# ESP32-S31 register map
Vendor: ESPRESSIF SYSTEMS (SHANGHAI) CO., LTD.; Series: ESP32 S-Series; File version: 1
CPU: RV32IMAFC r0p0, little endian, no MPU, FPU, 0 interrupt priority bits
Address unit: 32 bits
Registers are 32-bit, read-write, reset 0x0 unless marked. A register's access mark holds for its fields unless they carry their own. Offsets are from the block's base; [hi:lo] are bit positions; {n}, {i} and the like mark numbered series.

## LEDC0 — LEDC0 Peripheral
Base 0x20392000
Same registers: LEDC1 0x2039C000
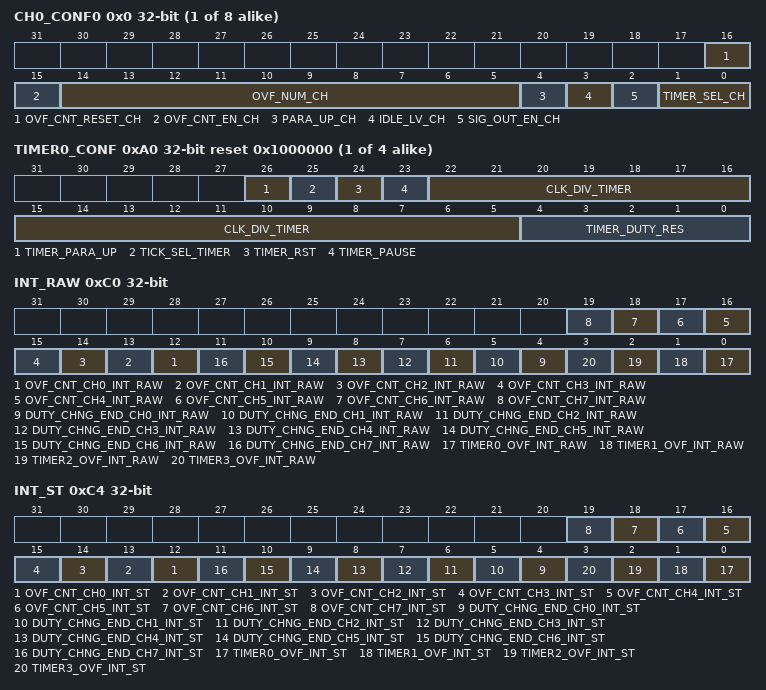
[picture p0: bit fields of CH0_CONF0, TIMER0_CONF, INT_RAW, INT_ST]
{0x0+0x14*i} CH{i}_CONF0 (i=0..7) access per field — Configuration register 0 for channel {i}
  [16] OVF_CNT_RESET_CH wo — Configures whether or not to reset the ovf_cnt of channel %s.\\0: Invalid. No effect\\1: Reset the ovf_cnt
  [15] OVF_CNT_EN_CH rw — Configures whether or not to enable the ovf_cnt of channel %s.\\0: Disable\\1: Enable
  [14:5] OVF_NUM_CH rw — Configures the maximum times of overflow minus 1.The LEDC_OVF_CNT_CH%s_INT interrupt will be triggered when channel %s overflows for (LEDC_OVF_NUM_CH%s + 1) times.
  [4] PARA_UP_CH wo — Configures whether or not to update LEDC_HPOINT_CH%s, LEDC_DUTY_START_CH%s, LEDC_SIG_OUT_EN_CH%s, LEDC_TIMER_SEL_CH%s, LEDC_OVF_CNT_EN_CH%s fields and duty cycle range configuration for channel %s, and will be automatically cleared by hardware.\\0: Invalid. No effect\\1: Update
  [3] IDLE_LV_CH rw — Configures the output value when channel %s is inactive. Valid only when LEDC_SIG_OUT_EN_CH%s is 0.\\0: Output level is low\\1: Output level is high
  [2] SIG_OUT_EN_CH rw — Configures whether or not to enable signal output on channel %s.\\0: Signal output disable\\1: Signal output enable
  [1:0] TIMER_SEL_CH rw — Configures which timer is channel %s selected.\\0: Select timer0\\1: Select timer1\\2: Select timer2\\3: Select timer3
{0x4+0x14*i} CH{i}_HPOINT (i=0..7) — High point register for channel {i}
  [19:0] HPOINT_CH — Configures high point of signal output on channel %s. The output value changes to high when the selected timers has reached the value specified by this register.
{0x8+0x14*i} CH{i}_DUTY (i=0..7) — Initial duty cycle register for channel {i}
  [24:0] DUTY_CH — Configures the duty of signal output on channel %s.
{0xC+0x14*i} CH{i}_CONF1 (i=0..7) — Configuration register 1 for channel {i}
  [31] DUTY_START_CH — Configures whether the duty cycle fading configurations take effect.\\0: Not take effect\\1: Take effect
{0x10+0x14*i} CH{i}_DUTY_R (i=0..7) ro — Current duty cycle register for channel {i}
  [24:0] DUTY_CH_R — Represents the current duty of output signal on channel %s.
{0xA0+8i} TIMER{i}_CONF (i=0..3) access per field reset 0x1000000 — Timer {i} configuration register
  [26] TIMER_PARA_UP wo — Configures whether or not to update LEDC_CLK_DIV_TIMER%s and LEDC_TIMER%s_DUTY_RES.\\0: Invalid. No effect\\1: Update
  [25] TICK_SEL_TIMER rw — Configures which clock is timer %s selected. Unused.
  [24] TIMER_RST rw — Configures whether or not to reset timer %s. The counter will show 0 after reset.\\0: Not reset\\1: Reset
  [23] TIMER_PAUSE rw — Configures whether or not to pause the counter in timer %s.\\0: Normal\\1: Pause
  [22:5] CLK_DIV_TIMER rw — Configures the divisor for the divider in timer %s.The least significant eight bits represent the fractional part.
  [4:0] TIMER_DUTY_RES rw — Configures the bit width of the counter in timer %s. Valid values are 1 to 20.
{0xA4+8i} TIMER{i}_VALUE (i=0..3) ro — Timer {i} current counter value register
  [19:0] TIMER_CNT — Represents the current counter value of timer %s.
0xC0 INT_RAW — Interrupt raw status register
  [n+12] OVF_CNT_CH{n}_INT_RAW (n=0..7) — Raw status bit: The raw interrupt status of LEDC_OVF_CNT_CH{n}_INT. Triggered when the ovf_cnt has reached the value specified by LEDC_OVF_NUM_CH{n}.
  [n+4] DUTY_CHNG_END_CH{n}_INT_RAW (n=0..7) — Raw status bit: The raw interrupt status of LEDC_DUTY_CHNG_END_CH{n}_INT. Triggered when the fading of duty has finished.
  [n] TIMER{n}_OVF_INT_RAW (n=0..3) — Raw status bit: The raw interrupt status of LEDC_TIMER{n}_OVF_INT. Triggered when the timer{n} has reached its maximum counter value.
0xC4 INT_ST ro — Interrupt masked status register
  [n+12] OVF_CNT_CH{n}_INT_ST (n=0..7) — Masked status bit: The masked interrupt status of LEDC_OVF_CNT_CH{n}_INT. Valid only when LEDC_OVF_CNT_CH{n}_INT_ENA is set to 1.
  [n+4] DUTY_CHNG_END_CH{n}_INT_ST (n=0..7) — Masked status bit: The masked interrupt status of LEDC_DUTY_CHNG_END_CH{n}_INT. Valid only when LEDC_DUTY_CHNG_END_CH{n}_INT_ENA is set to 1.
  [n] TIMER{n}_OVF_INT_ST (n=0..3) — Masked status bit: The masked interrupt status of LEDC_TIMER{n}_OVF_INT. Valid only when LEDC_TIMER{n}_OVF_INT_ENA is set to 1.
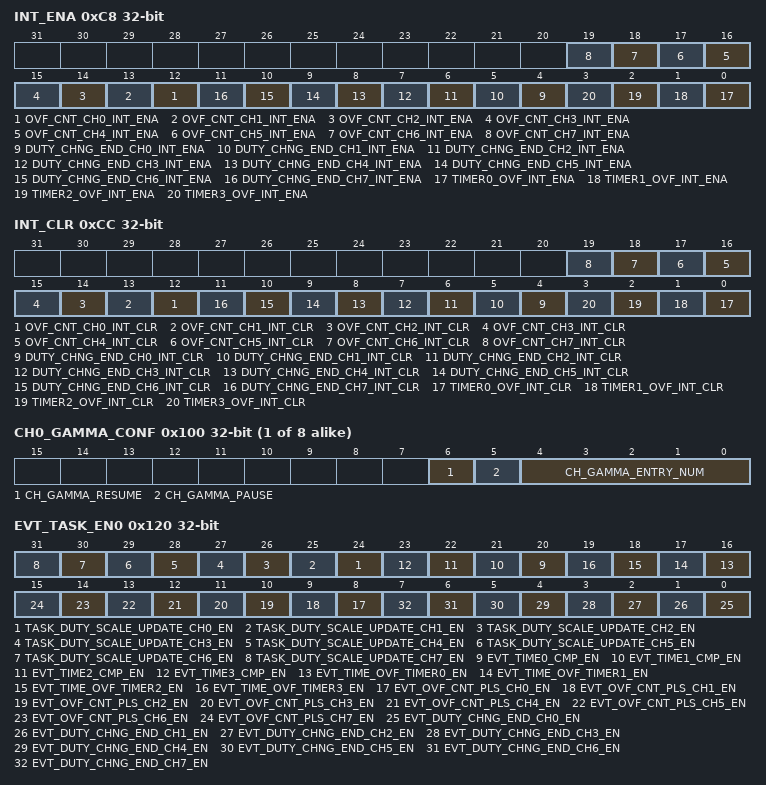
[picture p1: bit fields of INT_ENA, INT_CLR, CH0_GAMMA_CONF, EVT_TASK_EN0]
0xC8 INT_ENA — Interrupt enable register
  [n+12] OVF_CNT_CH{n}_INT_ENA (n=0..7) — Enable bit: Write 1 to enable LEDC_OVF_CNT_CH{n}_INT.
  [n+4] DUTY_CHNG_END_CH{n}_INT_ENA (n=0..7) — Enable bit: Write 1 to enable LEDC_DUTY_CHNG_END_CH{n}_INT.
  [n] TIMER{n}_OVF_INT_ENA (n=0..3) — Enable bit: Write 1 to enable LEDC_TIMER{n}_OVF_INT.
0xCC INT_CLR wo — Interrupt clear register
  [n+12] OVF_CNT_CH{n}_INT_CLR (n=0..7) — Clear bit: Write 1 to clear LEDC_OVF_CNT_CH{n}_INT.
  [n+4] DUTY_CHNG_END_CH{n}_INT_CLR (n=0..7) — Clear bit: Write 1 to clear LEDC_DUTY_CHNG_END_CH{n}_INT.
  [n] TIMER{n}_OVF_INT_CLR (n=0..3) — Clear bit: Write 1 to clear LEDC_TIMER{n}_OVF_INT.
{0x100+4i} CH{i}_GAMMA_CONF (i=0..7) access per field — Ledc ch{i} gamma config register.
  [6] CH_GAMMA_RESUME wo — Configures whether or nor to resume duty cycle fading of LEDC ch%s.\\0: Invalid. No effect\\1: Resume
  [5] CH_GAMMA_PAUSE wo — Configures whether or not to pause duty cycle fading of LEDC ch%s.\\0: Invalid. No effect\\1: Pause
  [4:0] CH_GAMMA_ENTRY_NUM rw — Configures the number of duty cycle fading rages for LEDC ch%s.
0x120 EVT_TASK_EN0 — Ledc event task enable bit register0.
  [n+24] TASK_DUTY_SCALE_UPDATE_CH{n}_EN (n=0..7) — Configures whether or not to enable the LEDC_TASK_DUTY_SCALE_UPDATE_CH{n} task.\\0: Disable\\1: Enable
  [n+20] EVT_TIME{n}_CMP_EN (n=0..3) — Configures whether or not to enable the LEDC_EVT_TIMER{n}_CMP event.\\0: Disable\\1: Enable
  [n+16] EVT_TIME_OVF_TIMER{n}_EN (n=0..3) — Configures whether or not to enable the LEDC_EVT_TIME_OVF_TIMER{n} event.\\0: Disable\\1: Enable
  [n+8] EVT_OVF_CNT_PLS_CH{n}_EN (n=0..7) — Configures whether or not to enable the LEDC_EVT_OVF_CNT_PLS_CH{n} event.\\0: Disable\\1: Enable
  [n] EVT_DUTY_CHNG_END_CH{n}_EN (n=0..7) — Configures whether or not to enable the LEDC_EVT_DUTY_CHNG_END_CH{n} event.\\0: Disable\\1: Enable
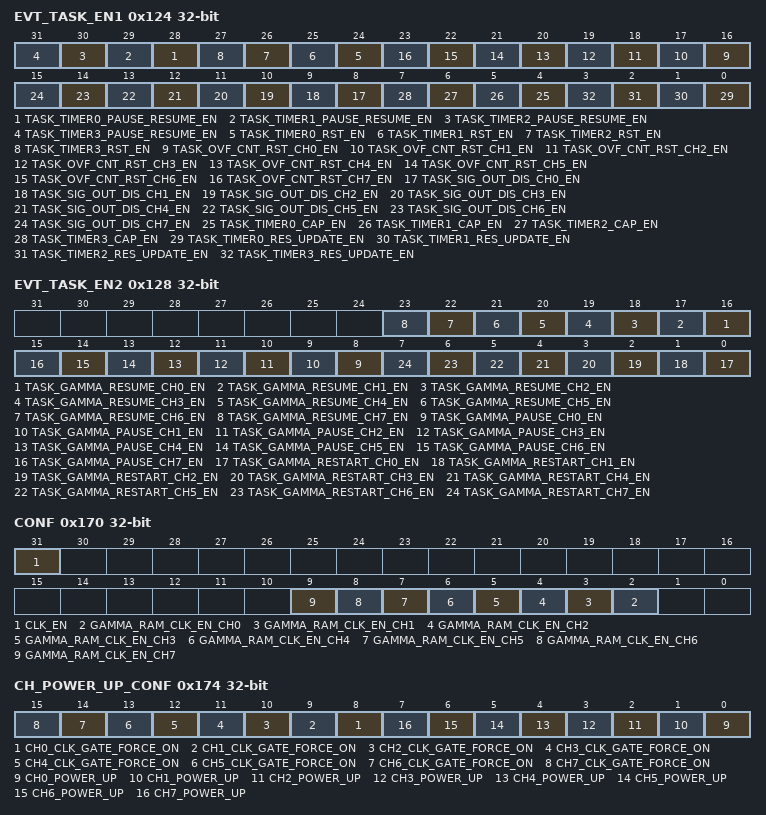
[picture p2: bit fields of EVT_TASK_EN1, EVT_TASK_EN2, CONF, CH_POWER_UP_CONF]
0x124 EVT_TASK_EN1 — Ledc event task enable bit register1.
  [n+28] TASK_TIMER{n}_PAUSE_RESUME_EN (n=0..3) — Configures whether or not to enable LEDC_TASK_TIMER{n}_PAUSE and LEDC_TASK_TIMER{n} _RESUME task.\\0: Disable\\1: Enable
  [n+24] TASK_TIMER{n}_RST_EN (n=0..3) — Configures whether or not to enable LEDC_TASK_TIMER{n}_RST task.\\0: Disable\\1: Enable
  [n+16] TASK_OVF_CNT_RST_CH{n}_EN (n=0..7) — Configures whether or not to enable LEDC_TASK_OVF_CNT_RST_CH{n} task.\\0: Disable\\1: Enable
  [n+8] TASK_SIG_OUT_DIS_CH{n}_EN (n=0..7) — Configures whether or not to enable LEDC_TASK_SIG_OUT_DIS_CH{n} task.\\0: Disable\\1: Enable
  [n+4] TASK_TIMER{n}_CAP_EN (n=0..3) — Configures whether or not to enable LEDC_TASK_TIMER{n}_CAP task.\\0: Disable\\1: Enable
  [n] TASK_TIMER{n}_RES_UPDATE_EN (n=0..3) — Configures whether or not to enable LEDC_TASK_TIMER{n}_RES_UPDATE task.\\0: Disable\\1: Enable
0x128 EVT_TASK_EN2 — Ledc event task enable bit register2.
  [n+16] TASK_GAMMA_RESUME_CH{n}_EN (n=0..7) — Configures whether or not to enable LEDC_TASK_GAMMA_RESUME_CH{n} task.\\0: Disable\\1: Enable
  [n+8] TASK_GAMMA_PAUSE_CH{n}_EN (n=0..7) — Configures whether or not to enable LEDC_TASK_GAMMA_PAUSE_CH{n} task.\\0: Disable\\1: Enable
  [n] TASK_GAMMA_RESTART_CH{n}_EN (n=0..7) — Configures whether or not to enable LEDC_TASK_GAMMA_RESTART_CH{n} task.\\0: Disable\\1: Enable
{0x140+4i} TIMER{i}_CMP (i=0..3) — Ledc timer{i} compare value register.
  [19:0] TIMER_CMP — Configures the comparison value for LEDC timer%s.
{0x150+4i} TIMER{i}_CNT_CAP (i=0..3) ro — Ledc timer{i} captured count value register.
  [19:0] TIMER_CNT_CAP — Represents the captured LEDC timer%s count value.
0x170 CONF — LEDC global configuration register
  [31] CLK_EN — Configures whether or not to open register clock gate.\\0: Open the clock gate only when application writes registers\\1: Force open the clock gate for register
  [n+2] GAMMA_RAM_CLK_EN_CH{n} (n=0..7) — Configures whether or not to open LEDC ch{n} gamma ram clock gate.\\0: Open the clock gate only when application writes or reads LEDC ch{n} gamma ram\\1: Force open the clock gate for LEDC ch{n} gamma ram
0x174 CH_POWER_UP_CONF — LEDC channel power up configuration register
  [n+8] CH{n}_CLK_GATE_FORCE_ON (n=0..7) — Configures whether or not to open ch{n} clock gate.\\0: Open the clock gate only when ch{n} is power up\\1: Force open the clock gate for ch{n}
  [n] CH{n}_POWER_UP (n=0..7) — Configures whether or not to power up ch{n}.\\0: power down\\1: power up
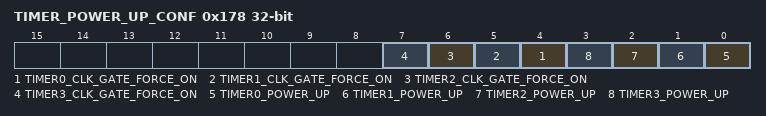
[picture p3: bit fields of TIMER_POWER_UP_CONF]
0x178 TIMER_POWER_UP_CONF — LEDC timer power up configuration register
  [n+4] TIMER{n}_CLK_GATE_FORCE_ON (n=0..3) — Configures whether or not to open timer{n} clock gate.\\0: Open the clock gate only when timer{n} is power up\\1: Force open the clock gate for timer{n}
  [n] TIMER{n}_POWER_UP (n=0..3) — Configures whether or not to power up timer{n}.\\0: power down\\1: power up
0x17C DATE reset 0x2501150 — Version control register
  [27:0] LEDC_DATE — Configures the version.
